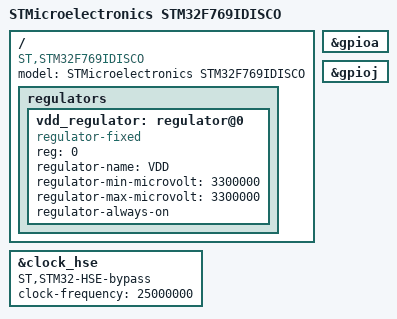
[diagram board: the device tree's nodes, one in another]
/**
 * \file
 * \brief Devicetree for STM32F769IDISCO
 *
 * \author Copyright (C) 2017 elbe informatik GmbH
 *
 * \par License
 * This Source Code Form is subject to the terms of the Mozilla Public License, v. 2.0. If a copy of the MPL was not
 * distributed with this file, You can obtain one at http://mozilla.org/MPL/2.0/.
 */

/dts-v1/;

#include "STM32F769NI.dtsi"

/ {
	compatible = "ST,STM32F769IDISCO", "ST,STM32F769NI";
	model = "STMicroelectronics STM32F769IDISCO";

	regulators {
		#address-cells = <1>;
		#size-cells = <0>;

		vdd_regulator: regulator@0 {
			compatible = "regulator-fixed";
			reg = <0>;
			regulator-name = "VDD";
			regulator-min-microvolt = <3300000>;
			regulator-max-microvolt = <3300000>;
			regulator-always-on;
		};
	};
};

&clock_hse {
	ST,STM32-HSE-bypass;
	clock-frequency = <25000000>;
};

&gpioa {
	status = "okay";
};
&gpioj {
	status = "okay";
};
